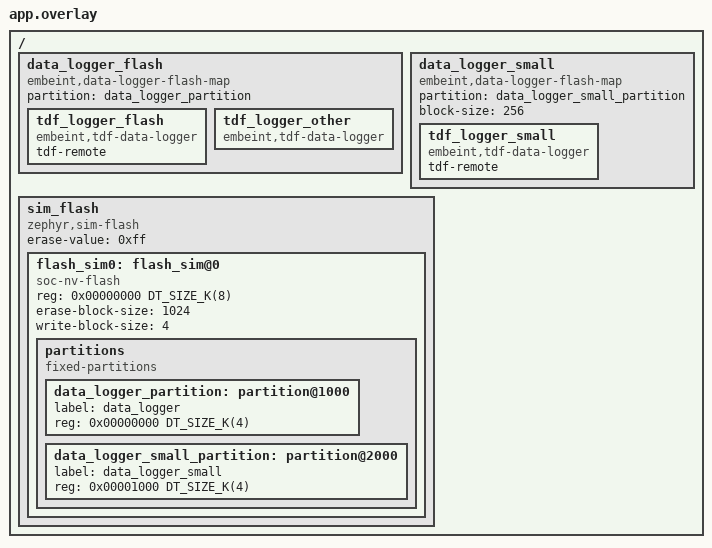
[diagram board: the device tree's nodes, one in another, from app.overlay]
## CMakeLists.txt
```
# SPDX-License-Identifier: Apache-2.0

cmake_minimum_required(VERSION 3.20.0)
find_package(Zephyr REQUIRED HINTS $ENV{ZEPHYR_BASE})
project(tdf_remote)

target_sources(app PRIVATE
  src/main.c
)
```

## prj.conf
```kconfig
CONFIG_ZTEST=y
CONFIG_FLASH=y
CONFIG_FLASH_SIMULATOR=y
CONFIG_FLASH_SIMULATOR_UNALIGNED_READ=y
CONFIG_FLASH_MAP=y
CONFIG_NET_BUF=y
CONFIG_DATA_LOGGER=y
CONFIG_DATA_LOGGER_FLASH_MAP=y
CONFIG_TDF_DATA_LOGGER=y
CONFIG_TDF=y
```

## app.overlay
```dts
#include <mem.h>

/ {
	data_logger_flash: data_logger_flash {
		compatible = "embeint,data-logger-flash-map", "embeint,data-logger";
		partition = <&data_logger_partition>;

		tdf_logger_flash: tdf_logger_flash {
			compatible = "embeint,tdf-data-logger";
			tdf-remote;
		};

		tdf_logger_other: tdf_logger_other {
			compatible = "embeint,tdf-data-logger";
		};
	};

	data_logger_small: data_logger_small {
		compatible = "embeint,data-logger-flash-map", "embeint,data-logger";
		partition = <&data_logger_small_partition>;
		block-size = <256>;

		tdf_logger_small: tdf_logger_small {
			compatible = "embeint,tdf-data-logger";
			tdf-remote;
		};
	};

	sim_flash: sim_flash {
		compatible = "zephyr,sim-flash";

		#address-cells = <1>;
		#size-cells = <1>;
		erase-value = <0xff>;

		flash_sim0: flash_sim@0 {
			compatible = "soc-nv-flash";
			reg = <0x00000000 DT_SIZE_K(8)>;

			erase-block-size = <1024>;
			write-block-size = <4>;

			partitions {
				compatible = "fixed-partitions";
				#address-cells = <1>;
				#size-cells = <1>;

				data_logger_partition: partition@1000 {
					label = "data_logger";
					reg = <0x00000000 DT_SIZE_K(4)>;
				};

				data_logger_small_partition: partition@2000 {
					label = "data_logger_small";
					reg = <0x00001000 DT_SIZE_K(4)>;
				};
			};
		};
	};
};
```

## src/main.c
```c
/**
 * @file
 * @copyright 2024 Embeint Holdings Pty Ltd
 * @author Jordan Yates <jordan@embeint.com>
 *
 * SPDX-License-Identifier: FSL-1.1-ALv2
 */

#include <stdint.h>

#include <zephyr/ztest.h>
#include <zephyr/kernel.h>
#include <zephyr/drivers/flash.h>
#include <zephyr/drivers/flash/flash_simulator.h>
#include <zephyr/sys/byteorder.h>

#include <infuse/epacket/packet.h>
#include <infuse/data_logger/logger.h>
#include <infuse/data_logger/high_level/tdf.h>

enum {
	TDF_RANDOM = 37,
};

static uint8_t *flash_buffer;
static size_t flash_buffer_size;
static uint8_t block_buffer[512];

int tdf_data_logger_init(const struct device *dev);
int logger_flash_map_init(const struct device *dev);

static void validate_tdf_remote(const struct device *dev, uint32_t block, uint64_t expected_id)
{
	zassert_equal(0, data_logger_block_read(dev, block, 0, block_buffer, sizeof(block_buffer)));
	zassert_equal(INFUSE_TDF_REMOTE, block_buffer[1]);
	zassert_equal(expected_id, sys_get_le64(block_buffer + 2));
}

ZTEST(tdf_data_logger_remote, test_non_remote)
{
	const struct device *tdf_logger = DEVICE_DT_GET(DT_NODELABEL(tdf_logger_other));

	zassert_equal(-EINVAL, tdf_data_logger_remote_id_set(tdf_logger, 0x800012345678ABCD));
}

ZTEST(tdf_data_logger_remote, test_standard)
{
	const struct device *tdf_logger = DEVICE_DT_GET(DT_NODELABEL(tdf_logger_flash));
	const struct device *data_logger = DEVICE_DT_GET(DT_NODELABEL(data_logger_flash));
	struct data_logger_state state;
	uint8_t tdf_data[32];
	int rc;

	rc = tdf_data_logger_remote_id_set(tdf_logger, 0x800012345678ABCD);
	zassert_equal(0, rc);

	/* 20 bytes per log (3 overhead, 17 data) = 160 bytes */
	for (int i = 0; i < 8; i++) {
		rc = tdf_data_logger_log_dev(tdf_logger, TDF_RANDOM, 17, 0, tdf_data);
		zassert_equal(0, rc);
	}
	data_logger_get_state(data_logger, &state);
	zassert_equal(0, state.current_block);

	/* Flush logger */
	rc = tdf_data_logger_flush_dev(tdf_logger);
	zassert_true(rc > 0);
	data_logger_get_state(data_logger, &state);
	zassert_equal(1, state.current_block);

	/* Expected ID */
	validate_tdf_remote(data_logger, 0, 0x800012345678ABCD);

	/* Flushing here shouldn't do anything */
	rc = tdf_data_logger_flush_dev(tdf_logger);
	zassert_equal(0, rc);
	data_logger_get_state(data_logger, &state);
	zassert_equal(1, state.current_block);
}

ZTEST(tdf_data_logger_remote, test_id_change)
{
	const struct device *tdf_logger = DEVICE_DT_GET(DT_NODELABEL(tdf_logger_flash));
	const struct device *data_logger = DEVICE_DT_GET(DT_NODELABEL(data_logger_flash));
	struct data_logger_state state;
	uint8_t tdf_data[32];
	int rc;

	rc = tdf_data_logger_remote_id_set(tdf_logger, 0x800012345678ABCD);
	zassert_equal(0, rc);

	/* Log some data, then set the ID to the same */
	rc = tdf_data_logger_log_dev(tdf_logger, TDF_RANDOM, 17, 0, tdf_data);
	zassert_equal(0, rc);
	rc = tdf_data_logger_remote_id_set(tdf_logger, 0x800012345678ABCD);
	zassert_equal(0, rc);
	data_logger_get_state(data_logger, &state);
	zassert_equal(0, state.current_block);

	/* Change the ID, data should now flush */
	rc = tdf_data_logger_remote_id_set(tdf_logger, 0x12345678ABC0AAAA);
	zassert_true(rc > 0);
	data_logger_get_state(data_logger, &state);
	zassert_equal(1, state.current_block);
	validate_tdf_remote(data_logger, 0, 0x800012345678ABCD);

	/* Log more data and flush, ID on the block should be the new value */
	rc = tdf_data_logger_log_dev(tdf_logger, TDF_RANDOM, 17, 0, tdf_data);
	zassert_equal(0, rc);
	rc = tdf_data_logger_flush_dev(tdf_logger);
	zassert_true(rc > 0);
	data_logger_get_state(data_logger, &state);
	zassert_equal(2, state.current_block);
	validate_tdf_remote(data_logger, 1, 0x12345678ABC0AAAA);
}

ZTEST(tdf_data_logger_remote, test_too_large_for_remote)
{
	const struct device *tdf_logger = DEVICE_DT_GET(DT_NODELABEL(tdf_logger_small));
	const struct device *data_logger = DEVICE_DT_GET(DT_NODELABEL(data_logger_small));
	struct data_logger_state state;
	uint8_t tdf_data[245] = {0};
	int rc;

	rc = tdf_data_logger_remote_id_set(tdf_logger, 0x800012345678ABCD);
	zassert_equal(0, rc);

	/* Fits on an empty block, but not after the remote ID */
	rc = tdf_data_logger_log_dev(tdf_logger, TDF_RANDOM, sizeof(tdf_data), 0, tdf_data);
	zassert_equal(-ENOSPC, rc);

	/* Logger still usable */
	rc = tdf_data_logger_log_dev(tdf_logger, TDF_RANDOM, 17, 0, tdf_data);
	zassert_equal(0, rc);
	rc = tdf_data_logger_flush_dev(tdf_logger);
	zassert_true(rc > 0);
	data_logger_get_state(data_logger, &state);
	zassert_equal(1, state.current_block);
}

void data_logger_reset(void *fixture)
{
	const struct device *tdf_logger = DEVICE_DT_GET(DT_NODELABEL(tdf_logger_flash));
	const struct device *data_logger = DEVICE_DT_GET(DT_NODELABEL(data_logger_flash));
	const struct device *tdf_small = DEVICE_DT_GET(DT_NODELABEL(tdf_logger_small));
	const struct device *data_small = DEVICE_DT_GET(DT_NODELABEL(data_logger_small));

	/* Clear any pending data */
	tdf_data_logger_flush_dev(tdf_logger);
	tdf_data_logger_flush_dev(tdf_small);

	/* Erase amd reinitialise loggers */
	memset(flash_buffer, 0xFF, flash_buffer_size);
	logger_flash_map_init(data_logger);
	tdf_data_logger_init(tdf_logger);
	logger_flash_map_init(data_small);
	tdf_data_logger_init(tdf_small);
}

static bool test_data_init(const void *global_state)
{
	flash_buffer = flash_simulator_get_memory(DEVICE_DT_GET(DT_NODELABEL(sim_flash)),
						  &flash_buffer_size);
	return true;
}

ZTEST_SUITE(tdf_data_logger_remote, test_data_init, NULL, data_logger_reset, NULL, NULL);
```
